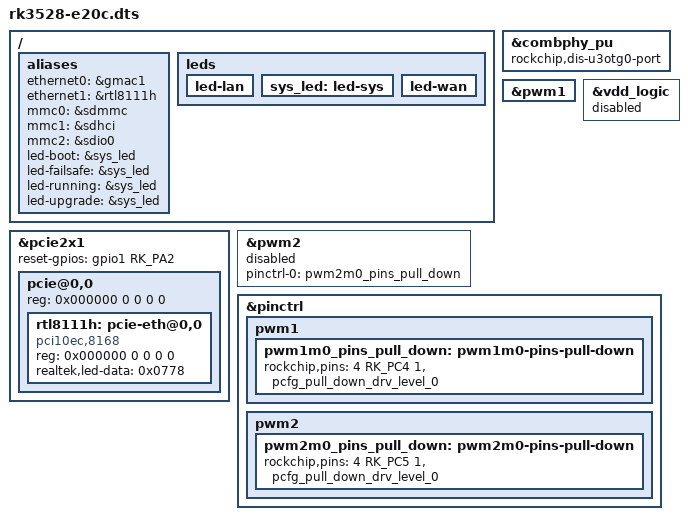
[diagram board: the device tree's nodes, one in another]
/dts-v1/;

#include <rockchip/rk3528-radxa-e20c.dts>
#include "rk3528-patch.dtsi"

/ {
	aliases {
		ethernet0 = &gmac1;
		ethernet1 = &rtl8111h;

		mmc0 = &sdmmc;
		mmc1 = &sdhci;
		mmc2 = &sdio0;

		led-boot = &sys_led;
		led-failsafe = &sys_led;
		led-running = &sys_led;
		led-upgrade = &sys_led;
	};

	leds {

		led-lan {

		};

		sys_led: led-sys {

		};

		led-wan {

		};
	};
};

&combphy_pu {
	rockchip,dis-u3otg0-port; /* disable USB3.0 */
	status = "okay";
};

&pcie2x1 {
	reset-gpios = <&gpio1 RK_PA2 GPIO_ACTIVE_HIGH>;
	status = "okay";
	pcie@0,0 {
		reg = <0x000000 0 0 0 0>;
		#address-cells = <3>;
		#size-cells = <2>;

		rtl8111h: pcie-eth@0,0 {
			compatible = "pci10ec,8168";
			reg = <0x000000 0 0 0 0>;
			realtek,led-data = <0x0778>;
		};
	};
};

&pwm1 {
	status = "okay";
};

// pwm2 hangs system, disable it
&vdd_logic {
	status = "disabled";
};

&pwm2 {
	pinctrl-0 = <&pwm2m0_pins_pull_down>;
	status = "disabled";
};

&pinctrl {
	pwm1 {
		pwm1m0_pins_pull_down: pwm1m0-pins-pull-down {
			rockchip,pins =
				/* pwm1_m0 */
				<4 RK_PC4 1 &pcfg_pull_down_drv_level_0>;
		};
	};
	pwm2 {
		pwm2m0_pins_pull_down: pwm2m0-pins-pull-down {
			rockchip,pins =
				/* pwm2_m0 */
				<4 RK_PC5 1 &pcfg_pull_down_drv_level_0>;
		};
	};
};
